AUTOSAR XML (schema 314)
package /ComponentType
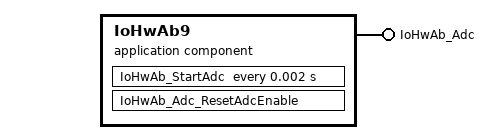
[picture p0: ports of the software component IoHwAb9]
  application software component type IoHwAb9
    provide port IoHwAb_Adc: server-com-spec{operation=ResetAdcEnable, queue-length=1}, provided-interface=IoHwAb_Adc
  internal behavior IoHwAb9_InternalBehavior: component=IoHwAb9, port-api-option{enable-take-address=false, indirect-api=false, port=IoHwAb_Adc}
    operation invoked event OIT_IoHwAb_Adc_ResetAdcEnable_IoHwAb_Adc_ResetAdcEnable: start-on-event=IoHwAb_Adc_ResetAdcEnable, operation=IoHwAb_Adc.ResetAdcEnable
    timing event TMT_IoHwAb_StartAdc: start-on-event=IoHwAb_StartAdc, period=0.002
    runnable IoHwAb_Adc_ResetAdcEnable
    runnable IoHwAb_StartAdc
  swc implementation IoHwAb9_Implementation: behavior=IoHwAb9_InternalBehavior
    code-descriptors:
      code Code: type=SRC
